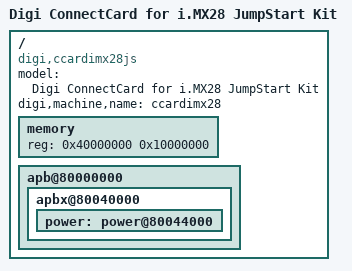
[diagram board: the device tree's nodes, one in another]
/*
 * Copyright 2013 Digi International, Inc.
 *
 * The code contained herein is licensed under the GNU General Public
 * License. You may obtain a copy of the GNU General Public License
 * Version 2 or later at the following locations:
 *
 * http://www.opensource.org/licenses/gpl-license.html
 * http://www.gnu.org/copyleft/gpl.html
 */

/dts-v1/;
#include "imx28.dtsi"

/*
 * This DTS file is made of small Device Tree fragments that can be
 * separately included or excluded to match a custom hardware configuration.
 * Remember to consult the documentation to prevent conflicts between
 * multiplexed devices.
 */

/* CPU frequency scaling */
#include "digi/ccardimx28/ccardimx28_cpufreq.dtsi"

/* NAND Flash */
#include "digi/ccardimx28/ccardimx28_nand.dtsi"

/* DUART */
#include "digi/ccardimx28/ccardimx28_duart_i2c0.dtsi"

/* Ethernet */
#include "digi/ccardimx28/ccardimx28_ethernet0.dtsi"
#include "digi/ccardimx28/ccardimx28_ethernet0_leds.dtsi"
#include "digi/ccardimx28/ccardimx28_ethernet1.dtsi"
/* #include "digi/ccardimx28/ccardimx28_ethernet1_leds.dtsi" */

/* AUARTs (and Bluetooth) */
#include "digi/ccardimx28/ccardimx28_auart0_bluetooth.dtsi"
#include "digi/ccardimx28/ccardimx28_auart1_2wires.dtsi"
/* #include "digi/ccardimx28/ccardimx28_auart1_4wires.dtsi" */
/* #include "digi/ccardimx28/ccardimx28_auart2_2wires.dtsi" */
/* #include "digi/ccardimx28/ccardimx28_auart2_4wires.dtsi" */
/* #include "digi/ccardimx28/ccardimx28_auart3_2wires.dtsi" */
/* #include "digi/ccardimx28/ccardimx28_auart3_4wires.dtsi" */
/* #include "digi/ccardimx28/ccardimx28_auart4_2wires.dtsi" */
/* #include "digi/ccardimx28/ccardimx28_auart4_4wires.dtsi" */

/* SSP (and WiFi) */
#include "digi/ccardimx28/ccardimx28_ssp0_mmc.dtsi"
/* #include "digi/ccardimx28/ccardimx28_ssp0_spi.dtsi" */
/* #include "digi/ccardimx28/ccardimx28_ssp0_spi_gpio.dtsi" */
/* #include "digi/ccardimx28/ccardimx28_ssp1_spi.dtsi" */
/* #include "digi/ccardimx28/ccardimx28_ssp1_spi_gpio.dtsi" */
/* #include "digi/ccardimx28/ccardimx28_ssp1_spi_gpio_spidev.dtsi" */
#include "digi/ccardimx28/ccardimx28_ssp2_mmc_wifi.dtsi"
/* #include "digi/ccardimx28/ccardimx28_ssp3_spi.dtsi" */
/* #include "digi/ccardimx28/ccardimx28_ssp3_spi_gpio.dtsi" */
/* #include "digi/ccardimx28/ccardimx28_ssp3_spi_gpio_spidev.dtsi" */

/* CAN */
#include "digi/ccardimx28/ccardimx28_can0.dtsi"
#include "digi/ccardimx28/ccardimx28_can1.dtsi"

/* I2C */
/* #include "digi/ccardimx28/ccardimx28_i2c0.dtsi" */
#include "digi/ccardimx28/ccardimx28_i2c1.dtsi"

/* Sound */
#include "digi/ccardimx28/ccardimx28_sound_i2c1.dtsi"

/* 1-wire */
#include "digi/ccardimx28/ccardimx28_onewire_i2c1.dtsi"

/* USB */
#include "digi/ccardimx28/ccardimx28_usb0.dtsi"
/* #include "digi/ccardimx28/ccardimx28_usb1.dtsi" */

/* Display */
/* #include "digi/ccardimx28/ccardimx28_display_lq70y3dg3b.dtsi" */

/* LRADC */
#include "digi/ccardimx28/ccardimx28_lradc.dtsi"
/* #include "digi/ccardimx28/ccardimx28_lradc_touchscreen.dtsi" */

/* Power */
#include "digi/ccardimx28/ccardimx28_power.dtsi"

/* Platform */
/ {
	model = "Digi ConnectCard for i.MX28 JumpStart Kit";
	compatible = "digi,ccardimx28js", "digi,ccardimx28", "fsl,imx28";
        digi,machine,name = "ccardimx28";
	memory {
		/*
		 * The kernel will update this to reflect the real
		 * RAM memory size as passed by U-Boot through MEM_ATAGs
		 */
		reg = <0x40000000 0x10000000>;
	};

	apb@80000000 {
		apbx@80040000 {
			power: power@80044000 {
				status = "okay";
			};
		};
	};
};
